# STM32U5Gx register map
File version: 1.0
CPU: CM33 r0p1, little endian, MPU, FPU, 4 interrupt priority bits
Registers are 32-bit, read-write, reset 0x0 unless marked. A register's access mark holds for its fields unless they carry their own. Offsets are from the block's base; [hi:lo] are bit positions; {n}, {i} and the like mark numbered series; <NAME> marks a mode.

## PWR — Power control
Base 0x46020800
Same registers: SEC_PWR 0x56020800
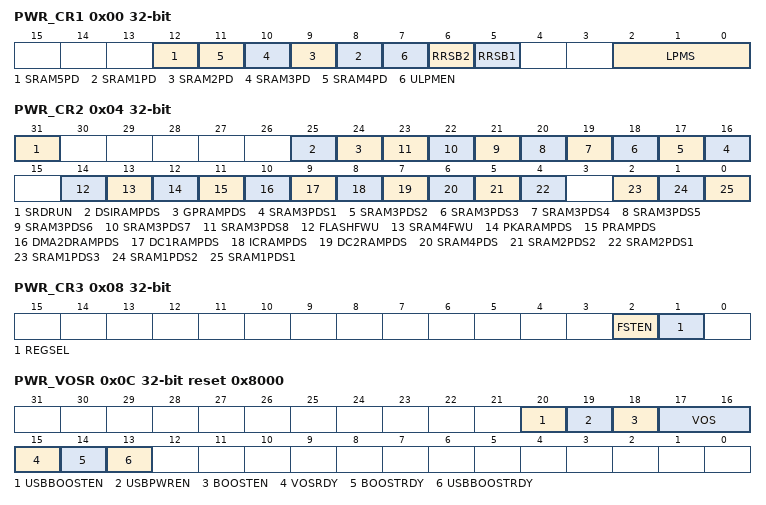
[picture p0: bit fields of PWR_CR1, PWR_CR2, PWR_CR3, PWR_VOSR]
0x00 PWR_CR1 — PWR control register 1
  [12] SRAM5PD — SRAM5 power down This bit is used to reduce the consumption by powering off the SRAM5. Note: This bit is only available in STM32U59x/5Ax. It is reserved in STM32U575/585.
    0=SRAM5 powered on; 1=SRAM5 powered off
  [n+7] SRAM{n}PD (n=1..4) — SRAM{n} power down This bit is used to reduce the consumption by powering off the SRAM{n}.
    0=SRAM{n} powered on; 1=SRAM{n} powered off
  [7] ULPMEN — BOR ultra-low power mode This bit is used to reduce the consumption by configuring the BOR in discontinuous mode. This bit must be set to reach the lowest power consumption in the low-power modes.
    0=BOR operating in continuous (normal) mode in Stop 1, Stop 2, Stop 3 and Standby modes and when the regulator is in range 4 (Run, Sleep or Stop 0 mode); 1=BOR operating in discontinuous (ultra-low power) mode in Stop 1, Stop 2, Stop 3 and Standby modes, and when the regulator is in range 4 (Run, Sleep or Stop 0 mode)
  [6] RRSB2 — SRAM2 page 2 retention in Stop 3 and Standby modes This bit is used to keep the SRAM2 page 2 content in Stop 3 and Standby modes. The SRAM2 page 2 corresponds to the last 56 Kbytes of the SRAM2 (from SRAM2 base address + 0x2000 to SRAM2 base address + 0xFFFF). Note: This bit has no effect in Shutdown mode.
    0=SRAM2 page2 content not retained in Stop3 and Standby modes; 1=SRAM2 page2 content retained in Stop 3 and Standby modes
  [5] RRSB1 — SRAM2 page 1 retention in Stop 3 and Standby modes This bit is used to keep the SRAM2 page 1 content in Stop 3 and Standby modes. The SRAM2 page 1 corresponds to the first 8 Kbytes of the SRAM2 (from SRAM2 base address to SRAM2 base address + 0x1FFF). Note: This bit has no effect in Shutdown mode.
    0=SRAM2 page1 content not retained in Stop 3 and Standby modes; 1=SRAM2 page1 content retained in Stop 3 and Standby modes
  [2:0] LPMS — Low-power mode selection These bits select the low-power mode entered when the CPU enters the Deepsleep mode. 10x: Standby mode (Standby mode also entered if LPMS = 11X in PWR_CR1 with BREN = 1 in PWR_BDCR1) 11x: Shutdown mode if BREN = 0 in PWR_BDCR1
    {v}=Stop {v} mode (v=0..3)
0x04 PWR_CR2 — PWR control register 2
  [31] SRDRUN — SmartRun domain in Run mode
    0=SmartRun domain AHB3 and APB3 clocks disabled by default in Stop 0,1, 2 modes; 1=SmartRun domain AHB3 and APB3 clocks kept enabled in Stop 0,1, 2 modes
  [25] DSIRAMPDS — DSI SRAM power-down in Stop modes (Stop 0, 1) DSI SRAM content is always lost in Stop 2 and Stop 3 modes. Note: This bit is only available in STM32U59x/5Ax. It is reserved in STM32U575/585.
    0=DSI SRAM content retained in Stop 0 and Stop 1 modes; 1=DSI SRAM content lost in Stop 0 and Stop 1 modes
  [24] GPRAMPDS — Graphic peripherals (LTDC, GFXMMU) SRAM power-down in Stop modes (Stop 0, 1, 2, 3) Note: LTDC SRAM content is always lost in Stop 2 and Stop 3 modes. It can be retained only in Stop 0 and Stop 1 modes. This bit is only available in STM32U59x/5Ax. It is reserved in STM32U575/585.
    0=Graphic peripherals SRAM content retained in Stop modes; 1=Graphic peripherals SRAM content lost in Stop modes
  [n+15] SRAM3PDS{n} (n=1..8) — SRAM3 page {n} (64 Kbytes) power-down in Stop modes (Stop 0, 1, 2, 3)
    0=SRAM3 page {n} content retained in Stop modes; 1=SRAM3 page {n} content lost in Stop modes
  [14] FLASHFWU — Flash memory fast wakeup from Stop 0 and Stop 1 modes This bit is used to obtain the best trade-off between low-power consumption and wakeup time when exiting the Stop 0 or Stop 1 modes. When this bit is set, the Flash memory remains in normal mode in Stop 0 and Stop 1 modes, which offers a faster startup time with higher consumption.
    0=Flash memory enters low-power mode in Stop 0 and Stop 1 modes (lower-power consumption); 1=Flash memory remains in normal mode in Stop 0 and Stop 1 modes (faster wakeup time)
  [13] SRAM4FWU — SRAM4 fast wakeup from Stop 0, Stop 1 and Stop 2 modes This bit is used to obtain the best trade-off between low-power consumption and wakeup time. SRAM4 wakeup time increases the wakeup time when exiting Stop 0, 1 and 2 modes, and also increases the LPDMA access time to SRAM4 during Stop modes.
    0=SRAM4 enters low-power mode in Stop 0, 1 and 2 modes (source biasing for lower-power consumption); 1=SRAM4 remains in normal mode in Stop 0, 1 and 2 modes (higher consumption but no SRAM4 wakeup time)
  [12] PKARAMPDS — PKA32 SRAM power-down in Stop modes (Stop 0, 1, 2, 3)
    0=PKA SRAM content retained in Stop modes; 1=PKA SRAM content lost in Stop modes
  [11] PRAMPDS — FMAC, FDCAN and USB peripherals SRAM power-down in Stop modes (Stop 0, 1, 2, 3)
    0=FMAC, FDCAN and USB peripherals SRAM content retained in Stop modes; 1=FMAC, FDCAN and USB peripherals SRAM content lost in Stop modes
  [10] DMA2DRAMPDS — DMA2D SRAM power-down in Stop modes (Stop 0, 1, 2, 3)
    0=DMA2D SRAM content retained in Stop modes; 1=DMA2D SRAM content lost in Stop modes
  [9] DC1RAMPDS — DCACHE1 SRAM power-down in Stop modes (Stop 0, 1, 2, 3)
    0=DCACHE1 SRAM content retained in Stop modes; 1=DCACHE1 SRAM content lost in Stop modes
  [8] ICRAMPDS — ICACHE SRAM power-down in Stop modes (Stop 0, 1, 2, 3)
    0=ICACHE SRAM content retained in Stop modes; 1=ICACHE SRAM content lost in Stop modes
  [7] DC2RAMPDS — DCACHE2 SRAM power-down in Stop modes (Stop 0, 1, 2, 3) Note: This bit is only available in STM32U59x/5Ax. It is reserved in STM32U575/585.
    0=DCACHE2 SRAM content retained in Stop modes; 1=DCACHE2 SRAM content lost in Stop modes
  [6] SRAM4PDS — SRAM4 power-down in Stop modes (Stop 0, 1, 2, 3)
    0=SRAM4 content retained in Stop modes; 1=SRAM4 content lost in Stop modes
  [5] SRAM2PDS2 — SRAM2 page 2 (56 Kbytes) power-down in Stop modes (Stop 0, 1, 2) Note: The SRAM2 page 2 retention in Stop 3 is controlled by RRSB2 bit in PWR_CR1.
    0=SRAM2 page 2 content retained in Stop modes; 1=SRAM2 page 2 content lost in Stop modes
  [4] SRAM2PDS1 — SRAM2 page 1 (8 Kbytes) power-down in Stop modes (Stop 0, 1, 2) Note: The SRAM2 page 1 retention in Stop 3 is controlled by RRSB1 bit in PWR_CR1.
    0=SRAM2 page 1 content retained in Stop modes; 1=SRAM2 page 1 content lost in Stop modes
  [2] SRAM1PDS3 — SRAM1 page 3 (64 Kbytes) power-down in Stop modes (Stop 0, 1, 2, 3)
    0=SRAM1 page 3 content retained in Stop modes; 1=SRAM1 page 3 content lost in Stop modes
  [1] SRAM1PDS2 — SRAM1 page 2 (64 Kbytes) power-down in Stop modes (Stop 0, 1, 2, 3)
    0=SRAM1 page 2 content retained in Stop modes; 1=SRAM1 page 2 content lost in Stop modes
  [0] SRAM1PDS1 — SRAM1 page 1 (64 Kbytes) power-down in Stop modes (Stop 0, 1, 2, 3)
    0=SRAM1 page 1 content retained in Stop modes; 1=SRAM1 page 1 content lost in Stop modes
0x08 PWR_CR3 — PWR control register 3
  [2] FSTEN — Fast soft start
    0=LDO/SMPS fast startup disabled (limited inrush current); 1=LDO/SMPS fast startup enabled
  [1] REGSEL — Regulator selection Note: REGSEL is reserved and must be kept at reset value in packages without SMPS.
    0=LDO selected; 1=SMPS selected
0x0C PWR_VOSR reset 0x8000 — PWR voltage scaling register
  [20] USBBOOSTEN — USB EPOD booster enable This bit is protected against non-secure access when SYSCLKSEC = 1 in RCC_SECCFGR. It is protected against unprivileged access when SYSCLKSEC = 1 in RCC_SECCFGR and SPRIV = 1 in PWR_PRIVCFGR, or when SYSCLKSEC = 0 and NSPRIV = 1. This bit must be set in range 1 and range 2 before enabling the USB peripheral. This bit is reset when going into Stop modes (0, 1, 2, 3). Note: This bit is only available in STM32U59x/5Ax. It is reserved in STM32U575/585.
    0=USB booster disabled; 1=USB booster enabled
  [19] USBPWREN — USB power enable This bit is protected against non-secure access when SYSCLKSEC = 1 in RCC_SECCFGR. It is protected against unprivileged access when SYSCLKSEC = 1 in RCC_SECCFGR and SPRIV = 1 in PWR_PRIVCFGR, or when SYSCLKSEC = 0 and NSPRIV = 1. Note: This bit is only available in STM32U59x/5Ax. It is reserved in STM32U575/585.
    0=USB power disabled; 1=USB power enabled
  [18] BOOSTEN — EPOD booster enable This bit is protected against non-secure access when SYSCLKSEC = 1 in RCC_SECCFGR. It is protected against unprivileged access when SYSCLKSEC = 1 in RCC_SECCFGR and SPRIV = 1 in PWR_PRIVCFGR, or when SYSCLKSEC = 0 and NSPRIV = 1. This bit must be set in range 1 and range 2 before increasing the system clock frequency above 50 MHz. This bit is reset when going into Stop modes (0, 1, 2, 3).
    0=Booster disabled; 1=Booster enabled
  [17:16] VOS — Voltage scaling range selection This field is protected against non-secure access when SYSCLKSEC = 1 in RCC_SECCFGR. It is protected against unprivileged access when SYSCLKSEC = 1 in RCC_SECCFGR and SPRIV = 1 in PWR_PRIVCFGR, or when SYSCLKSEC = 0 and NSPRIV = 1.
    0=Range 4 (lowest power); 1=Range 3; 2=Range 2; 3=Range 1 (highest frequency). This value cannot be written when VCOREMEN = 1 in TAMP_OR register.
  [15] VOSRDY ro — Ready bit for VCORE voltage scaling output selection
    0=Not ready, voltage level < VOS selected level; 1=Ready, voltage level ≥ VOS selected level
  [14] BOOSTRDY ro — EPOD booster ready This bit is set to 1 by hardware when the power booster startup time is reached. The system clock frequency can be switched higher than 50 MHz only after this bit is set.
    0=Power booster not ready; 1=Power booster ready
  [13] USBBOOSTRDY ro — USB EPOD booster ready This bit is set to 1 by hardware when the power booster startup time is reached. The USB clock can be provided only after this bit is set. Note: This bit is only available in STM32U59x/5Ax. It is reserved in STM32U575/585.
    0=USB power booster not ready; 1=USB power booster ready
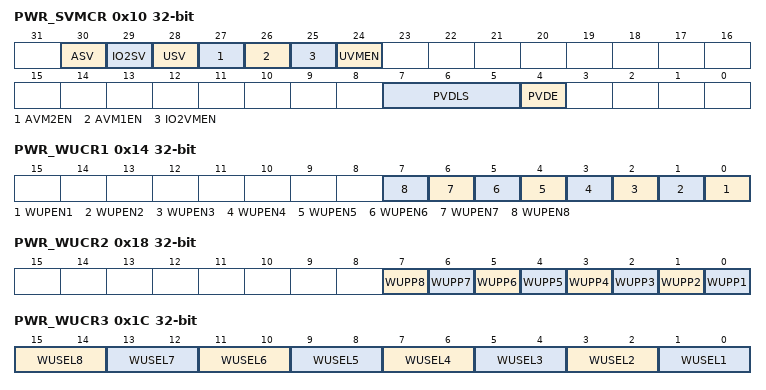
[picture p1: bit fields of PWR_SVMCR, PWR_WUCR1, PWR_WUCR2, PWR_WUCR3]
0x10 PWR_SVMCR — PWR supply voltage monitoring control register
  [30] ASV — VDDA independent analog supply valid This bit is used to validate the VDDA supply for electrical and logical isolation purpose. Setting this bit is mandatory to use the analog peripherals. If VDDA is not always present in the application, the VDDA voltage monitor can be used to determine whether this supply is ready or not.
    0=VDDA not present: logical and electrical isolation is applied to ignore this supply; 1=VDDA valid
  [29] IO2SV — VDDIO2 independent I/Os supply valid This bit is used to validate the VDDIO2 supply for electrical and logical isolation purpose. Setting this bit is mandatory to use PG[15:2]. If VDDIO2 is not always present in the application, the VDDIO2 voltage monitor can be used to determine whether this supply is ready or not.
    0=VDDIO2 not present: logical and electrical isolation is applied to ignore this supply; 1=VDDIO2 valid
  [28] USV — VDDUSB independent USB supply valid This bit is used to validate the VDDUSB supply for electrical and logical isolation purpose. Setting this bit is mandatory to use the USB OTG peripheral. If VDDUSB is not always present in the application, the VDDUSB voltage monitor can be used to determine whether this supply is ready or not.
    0=VDDUSB not present: logical and electrical isolation is applied to ignore this supply; 1=VDDUSB valid
  [27] AVM2EN — VDDA independent analog supply voltage monitor 2 enable (1.8 V threshold)
    0=VDDA voltage monitor 2 disabled; 1=VDDA voltage monitor 2 enabled
  [26] AVM1EN — VDDA independent analog supply voltage monitor 1 enable (1.6 V threshold)
    0=VDDA voltage monitor 1 disabled; 1=VDDA voltage monitor 1 enabled
  [25] IO2VMEN — VDDIO2 independent I/Os voltage monitor enable
    0=VDDIO2 voltage monitor disabled; 1=VDDIO2 voltage monitor enabled
  [24] UVMEN — VDDUSB independent USB voltage monitor enable
    0=VDDUSB voltage monitor disabled; 1=VDDUSB voltage monitor enabled
  [7:5] PVDLS — Power voltage detector level selection These bits select the voltage threshold detected by the power voltage detector:
    0=VPVD0 around 2.0 V; 1=VPVD1 around 2.2 V; 2=VPVD2 around 2.4 V; 3=VPVD3 around 2.5 V; 4=VPVD4 around 2.6 V; 5=VPVD5 around 2.8 V; 6=VPVD6 around 2.9 V; 7=External input analog voltage PVD_IN (compared internally to VREFINT)
  [4] PVDE — Power voltage detector enable
    0=Power voltage detector disabled; 1=Power voltage detector enabled
0x14 PWR_WUCR1 — PWR wakeup control register 1
  [n-1] WUPEN{n} (n=1..8) — Wakeup pin WKUP{n} enable
    0=Wakeup pin WKUP{n} disabled; 1=Wakeup pin WKUP{n} enabled
0x18 PWR_WUCR2 — PWR wakeup control register 2
  [all] fields
    0=Detection on high level (rising edge); 1=Detection on low level (falling edge)
  [n-1] WUPP{n} (n=2..8) — Wakeup pin WKUP{n} polarity This bit must be configured when WUPEN{n} = 0.
  [0] WUPP1 — Wakeup pin WKUP1 polarity. This bit must be configured when WUPEN1 = 0.
0x1C PWR_WUCR3 — PWR wakeup control register 3
  [2n-1:2n-2] WUSEL{n} (n=2..8) — Wakeup pin WKUP{n} selection This field must be configured when WUPEN{n} = 0.
    {v}=WKUP{n}_{v} (v=0..3)
  [1:0] WUSEL1 — Wakeup pin WKUP1 selection This field must be configured when WUPEN1 = 0.
    {v}=WKUP0_{v} (v=0..3)
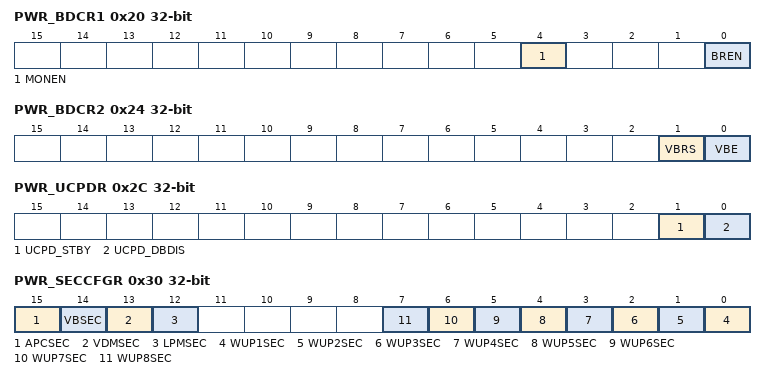
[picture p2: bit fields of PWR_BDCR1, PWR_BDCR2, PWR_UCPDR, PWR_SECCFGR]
0x20 PWR_BDCR1 — PWR Backup domain control register 1
  [4] MONEN — Backup domain voltage and temperature monitoring enable
    0=Backup domain voltage and temperature monitoring disabled; 1=Backup domain voltage and temperature monitoring enabled
  [0] BREN — Backup RAM retention in Standby and VBAT modes When this bit is set, the backup RAM content is kept in Standby and VBAT modes. If BREN is reset, the backup RAM can still be used in Run, Sleep and Stop modes. However, its content is lost in Standby, Shutdown and VBAT modes. This bit can be written only when the regulator is LDO, which must be configured before switching to SMPS. Note: Backup RAM cannot be preserved in Shutdown mode.
    0=Backup RAM content lost in Standby and VBAT modes; 1=Backup RAM content preserved in Standby and VBAT modes
0x24 PWR_BDCR2 — PWR Backup domain control register 2
  [1] VBRS — VBAT charging resistor selection
    0=Charge VBAT through a 5 kΩ resistor; 1=Charge VBAT through a 1.5 kΩ resistor
  [0] VBE — VBAT charging enable
    0=VBAT battery charging disabled; 1=VBAT battery charging enabled
0x28 PWR_DBPR — PWR disable Backup domain register
  [0] DBP — Disable Backup domain write protection In reset state, all registers and SRAM in Backup domain are protected against parasitic write access. This bit must be set to enable the write access to these registers.
    0=Write access to Backup domain disabled; 1=Write access to Backup domain enabled
0x2C PWR_UCPDR — PWR USB Type-C™ and Power Delivery register
  [1] UCPD_STBY — UCPD Standby mode When set, this bit is used to memorize the UCPD configuration in Standby mode. This bit must be written to 1 just before entering Standby mode when using UCPD. It must be written to 0 after exiting the Standby mode and before writing any UCPD registers.
  [0] UCPD_DBDIS — UCPD dead battery disable After exiting reset, the USB Type-C “dead battery” behavior is enabled, which may have a pull-down effect on CC1 and CC2 pins. It is recommended to disable it in all cases, either to stop this pull-down or to handover control to the UCPD (the UCPD must be initialized before doing the disable).
    0=UCPD dead battery pull-down behavior enabled on UCPDx_CC1 and UCPDx_CC2 pins; 1=UCPD dead battery pull-down behavior disabled on UCPDx_CC1 and UCPDx_CC2 pins
0x30 PWR_SECCFGR — PWR security configuration register
  [15] APCSEC — Pull-up/pull-down secure protection
    0=PWR_APCR can be read and written with secure or non-secure access; 1=PWR_APCR can be read and written only with secure access
  [14] VBSEC — Backup domain secure protection
    0=PWR_BDCR1, PWR_BDCR2 and PWR_DBPR can be read and written with secure or non-secure access; 1=PWR_BDCR1, PWR_BDCR2 and PWR_DBPR can be read and written only with secure access
  [13] VDMSEC — Voltage detection and monitoring secure protection
    0=PWR_SVMCR and PWR_CR3 can be read and written with secure or non-secure access; 1=PWR_SVMCR and PWR_CR3 can be read and written only with secure access
  [12] LPMSEC — Low-power modes secure protection
    0=PWR_CR1, PWR_CR2 and CSSF in the PWR_SR can be read and written with secure or non-secure access; 1=PWR_CR1, PWR_CR2, and CSSF in the PWR_SR can be read and written only with secure access
  [n-1] WUP{n}SEC (n=1..8) — WUP{n} secure protection
    0=Bits related to the WKUP{n} pin in PWR_WUCR1, PWR_WUCR2, PWR_WUCR3 and PWR_WUSCR can be read and written with secure or non-secure access; 1=Bits related to the WKUP{n} pin in PWR_WUCR1, PWR_WUCR2, PWR_WUCR3 and PWR_WUSCR can be read and written only with secure access
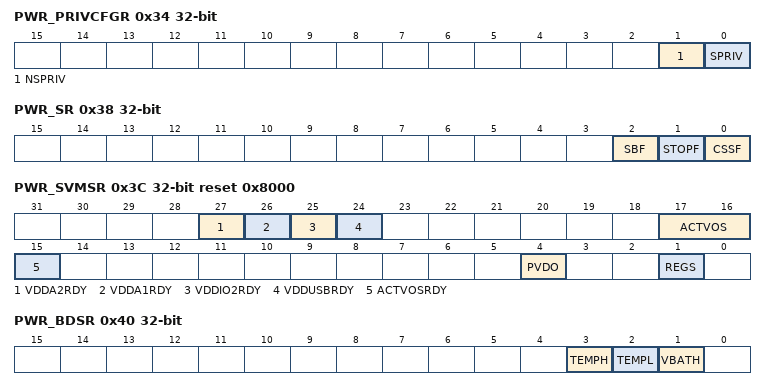
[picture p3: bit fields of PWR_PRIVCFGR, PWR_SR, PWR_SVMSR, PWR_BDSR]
0x34 PWR_PRIVCFGR — PWR privilege control register
  [1] NSPRIV — PWR non-secure functions privilege configuration This bit is set and reset by software. It can be written only by privileged access, secure or non-secure.
    0=Read and write to PWR non-secure functions can be done by privileged or unprivileged access; 1=Read and write to PWR non-secure functions can be done by privileged access only
  [0] SPRIV — PWR secure functions privilege configuration This bit is set and reset by software. It can be written only by a secure privileged access.
    0=Read and write to PWR secure functions can be done by privileged or unprivileged access; 1=Read and write to PWR secure functions can be done by privileged access only
0x38 PWR_SR — PWR status register
  [2] SBF ro — Standby flag This bit is set by hardware when the device enters the Standby mode, and is cleared by writing 1 to the CSSF bit, or by a power-on reset. It is not cleared by the system reset.
    0=The device did not enter Standby mode; 1=The device entered Standby mode
  [1] STOPF ro — Stop flag This bit is set by hardware when the device enters a Stop mode, and is cleared by software by writing 1 to the CSSF bit.
    0=The device did not enter any Stop mode; 1=The device entered a Stop mode
  [0] CSSF wo — Clear Stop and Standby flags This bit is protected against non-secure access when LPMSEC = 1 in PWR_SECCFGR. This bit is protected against unprivileged access when LPMSEC = 1 and SPRIV = 1 in PWR_PRIVCFGR, or when LPMSEC = 0 and NSPRIV = 1. Writing 1 to this bit clears the STOPF and SBF flags.
0x3C PWR_SVMSR ro reset 0x8000 — PWR supply voltage monitoring status register
  [27] VDDA2RDY — VDDA ready versus 1.8 V voltage monitor
    0=VDDA is below the threshold of the VDDA voltage monitor 2 (around 1.8 V); 1=VDDA is equal or above the threshold of the VDDA voltage monitor 2 (around 1.8 V)
  [26] VDDA1RDY — VDDA ready versus 1.6V voltage monitor
    0=VDDA is below the threshold of the VDDA voltage monitor 1 (around 1.6 V); 1=VDDA is equal or above the threshold of the VDDA voltage monitor 1 (around 1.6 V)
  [25] VDDIO2RDY — VDDIO2 ready
    0=VDDIO2 is below the threshold of the VDDIO2 voltage monitor; 1=VDDIO2 is equal or above the threshold of the VDDIO2 voltage monitor
  [24] VDDUSBRDY — VDDUSB ready
    0=VDDUSB is below the threshold of the VDDUSB voltage monitor; 1=VDDUSB is equal or above the threshold of the VDDUSB voltage monitor
  [17:16] ACTVOS — VOS currently applied to VCORE This field provides the last VOS value.
    0=Range 4 (lowest power); 1=Range 3; 2=Range 2; 3=Range 1 (highest frequency)
  [15] ACTVOSRDY — Voltage level ready for currently used VOS
    0=VCORE is above or below the current voltage scaling provided by ACTVOS[1:0]; 1=VCORE is equal to the current voltage scaling provided by ACTVOS[1:0]
  [4] PVDO — VDD voltage detector output
    0=VDD is equal or above the PVD threshold selected by PVDLS[2:0]; 1=VDD is below the PVD threshold selected by PVDLS[2:0]
  [1] REGS — Regulator selection
    0=LDO selected; 1=SMPS selected
0x40 PWR_BDSR ro — PWR Backup domain status register
  [3] TEMPH — Temperature level monitoring versus high threshold
    0=Temperature < high threshold; 1=Temperature ≥ high threshold
  [2] TEMPL — Temperature level monitoring versus low threshold
    0=Temperature > low threshold; 1=Temperature ≤ low threshold
  [1] VBATH — Backup domain voltage level monitoring versus high threshold
    0=Backup domain voltage level < high threshold; 1=Backup domain voltage level ≥ high threshold
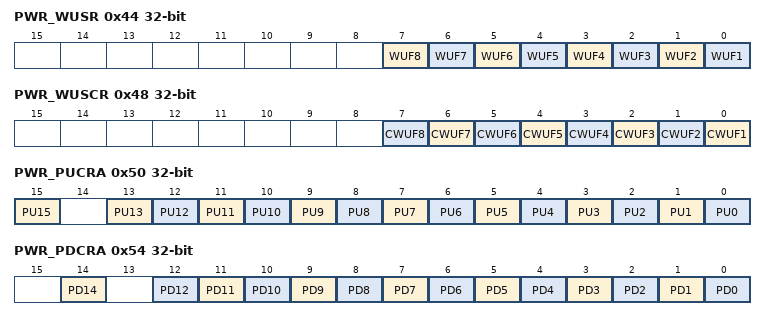
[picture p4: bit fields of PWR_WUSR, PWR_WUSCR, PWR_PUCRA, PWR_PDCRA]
0x44 PWR_WUSR ro — PWR wakeup status register
  [7] WUF8 — Wakeup flag 8 This bit is set when a wakeup event is detected on WKUP8 pin. This bit is cleared by writing 1 in the CWUF8 bit of PWR_WUSCR when WUSEL ≠ 11, or by hardware when WUPEN8 = 0. If WUSEL = 11, this bit is cleared by hardware when all internal wakeup source are cleared.
  [6] WUF7 — Wakeup flag 7 This bit is set when a wakeup event is detected on WKUP7 pin. This bit is cleared by writing 1 in the CWUF7 bit of PWR_WUSCR when WUSEL ≠ 11, or by hardware when WUPEN7 = 0. If WUSEL = 11, this bit is cleared by hardware when all internal wakeup source are cleared.
  [5] WUF6 — Wakeup flag 6 This bit is set when a wakeup event is detected on WKUP6 pin. This bit is cleared by writing 1 in the CWUF6 bit of PWR_WUSCR when WUSEL ≠ 11, or by hardware when WUPEN6 = 0. If WUSEL = 11, this bit is cleared by hardware when all internal wakeup source are cleared.
  [n-1] WUF{n} (n=1..5) — Wakeup flag {n} This bit is set when a wakeup event is detected on WKUP{n} pin. This bit is cleared by writing 1 in the CWUF{n} bit of PWR_WUSCR when WUSEL ≠ 11, or by hardware when WUPEN{n} = 0.
0x48 PWR_WUSCR — PWR wakeup status clear register
  [n-1] CWUF{n} wo (n=1..8) — Wakeup flag {n} Writing 1 to this bit clears the WUF{n} flag in PWR_WUSR.
0x4C PWR_APCR — PWR apply pull configuration register
  [0] APC — Apply pull-up and pull-down configuration When this bit is set, the I/O pull-up and pull-down configurations defined in PWR_PUCRx and PWR_PDCRx are applied. When this bit is cleared, PWR_PUCRx and PWR_PDCRx are not applied to the I/Os.
0x50 PWR_PUCRA — PWR port A pull-up control register
  [15] PU15 — Port A pull-up bit 15 When set, this bit activates the pull-up on PA15 when the APC bit is set in PWR_APCR. The pull-up is not activated if the corresponding PD15 bit is also set.
  [n] PU{n} (n=0..13)
0x54 PWR_PDCRA — PWR port A pull-down control register
  [14] PD14 — Port A pull-down bit 14 When set, this bit activates the pull-down on PA14 when the APC bit is set in PWR_APCR.
  [n] PD{n} (n=0..12)
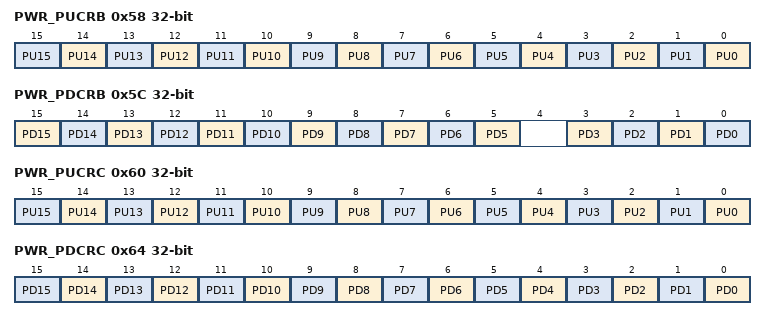
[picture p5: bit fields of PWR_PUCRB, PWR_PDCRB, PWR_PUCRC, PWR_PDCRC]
0x58 PWR_PUCRB — PWR port B pull-up control register
  [n] PU{n} (n=0..15)
0x5C PWR_PDCRB — PWR port B pull-down control register
  [n] PD{n} (n=5..15), [n] PD{n} (n=0..3)
0x60 PWR_PUCRC — Power port C pull up control register
  [n] PU{n} (n=0..15)
0x64 PWR_PDCRC — PWR port C pull-down control register
  [n] PD{n} (n=0..15)
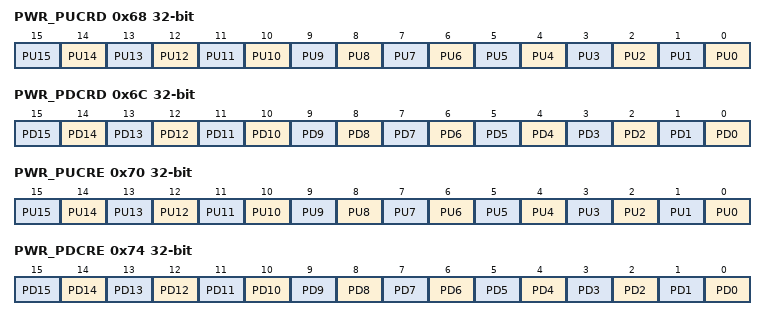
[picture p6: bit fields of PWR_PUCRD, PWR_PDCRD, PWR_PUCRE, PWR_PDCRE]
0x68 PWR_PUCRD — PWR port D pull-up control register
  [n] PU{n} (n=0..15)
0x6C PWR_PDCRD — PWR port D pull-down control register
  [n] PD{n} (n=0..15)
0x70 PWR_PUCRE — PWR port E pull-up control register
  [n] PU{n} (n=0..15)
0x74 PWR_PDCRE — PWR port E pull-down control register
  [n] PD{n} (n=0..15)
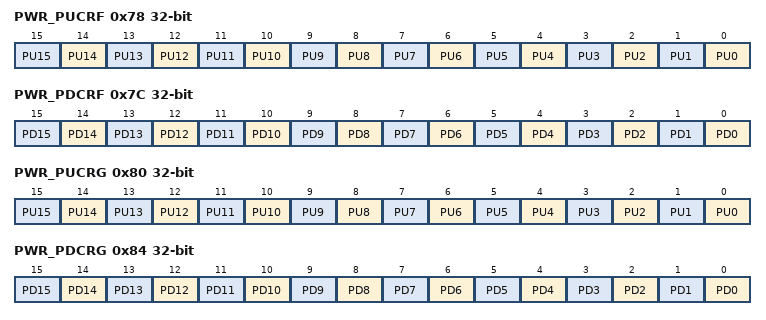
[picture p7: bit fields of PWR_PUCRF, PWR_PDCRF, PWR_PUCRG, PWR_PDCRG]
0x78 PWR_PUCRF — PWR port F pull-up control register
  [n] PU{n} (n=0..15)
0x7C PWR_PDCRF — PWR port F pull-down control register
  [n] PD{n} (n=0..15)
0x80 PWR_PUCRG — PWR port G pull-up control register
  [n] PU{n} (n=0..15)
0x84 PWR_PDCRG — PWR port G pull-down control register
  [n] PD{n} (n=0..15)
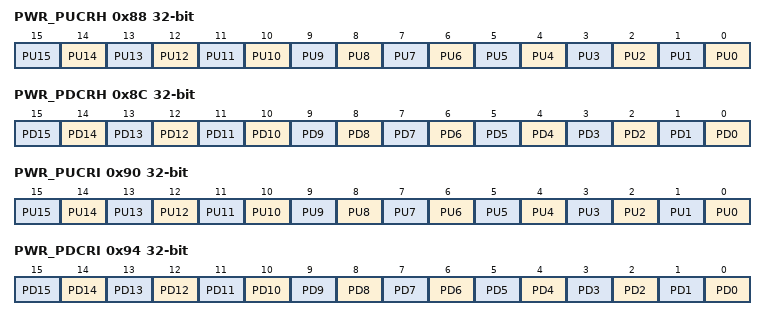
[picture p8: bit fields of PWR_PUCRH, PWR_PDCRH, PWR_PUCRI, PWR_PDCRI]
0x88 PWR_PUCRH — PWR port H pull-up control register
  [n] PU{n} (n=0..15)
0x8C PWR_PDCRH — PWR port H pull-down control register
  [n] PD{n} (n=0..15)
0x90 PWR_PUCRI — PWR port I pull-up control register
  [n] PU{n} (n=0..15)
0x94 PWR_PDCRI — PWR port I pull-down control register
  [n] PD{n} (n=0..15)
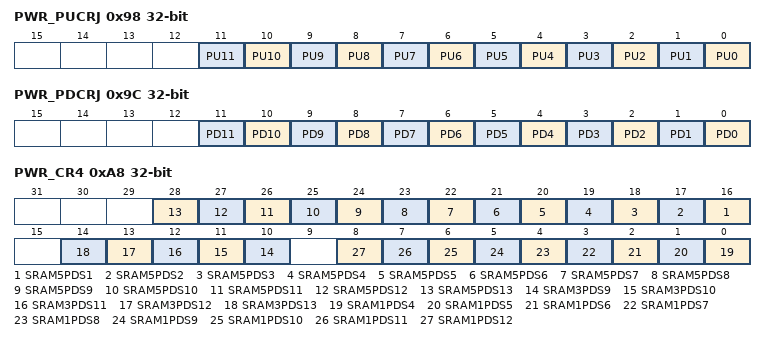
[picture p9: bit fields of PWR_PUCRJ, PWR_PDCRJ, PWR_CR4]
0x98 PWR_PUCRJ — PWR port J pull-up control register
  [n] PU{n} (n=0..11)
0x9C PWR_PDCRJ — PWR port J pull-down control register
  [n] PD{n} (n=0..11)
0xA8 PWR_CR4 — PWR control register 4
  [n+15] SRAM5PDS{n} (n=1..13), [n+1] SRAM3PDS{n} (n=9..13), [n-4] SRAM1PDS{n} (n=4..12)
